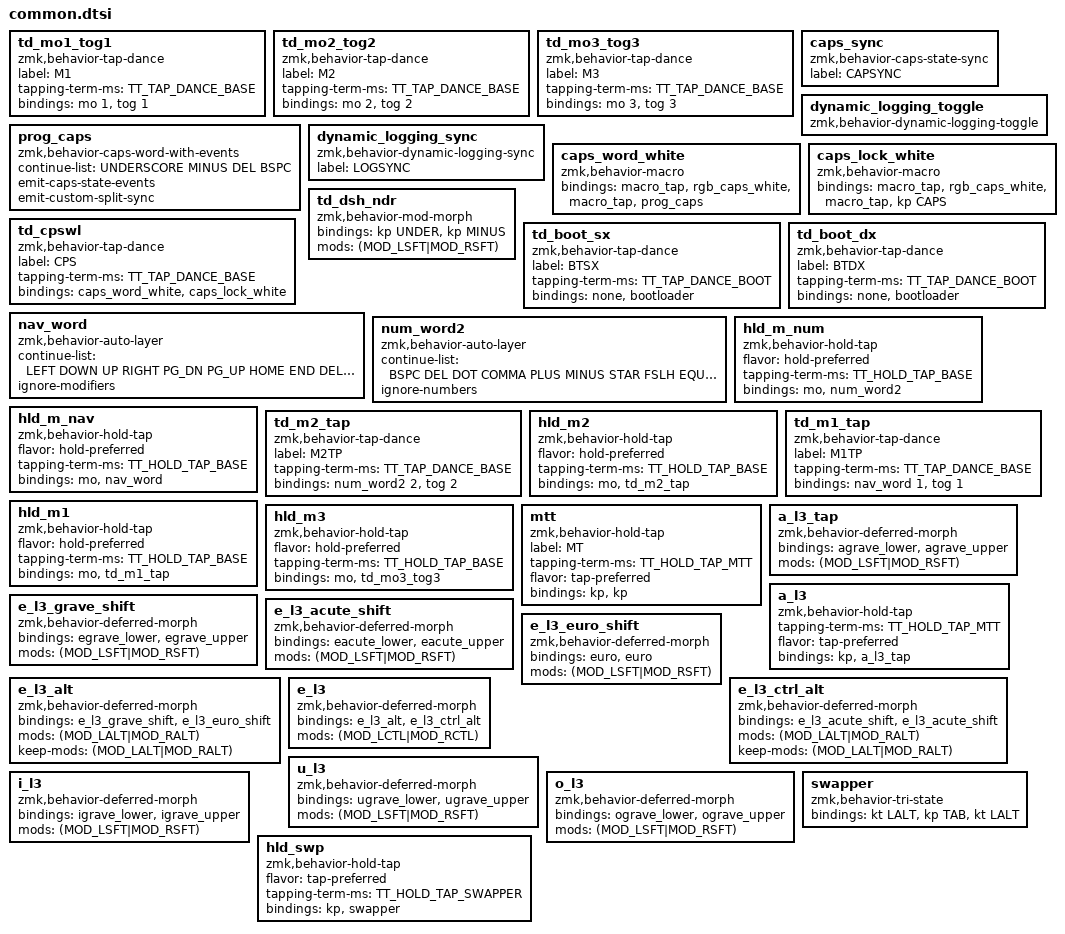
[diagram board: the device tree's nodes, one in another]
        /*
         * Mini-spec td_mo1_tog1
         * Input: tap dance su tasto M1.
         * Tap: layer momentaneo 1 (&mo 1).
         * Double tap: toggle persistente layer 1 (&tog 1).
         */
        td_mo1_tog1: td_mo1_tog1 {
            compatible = "zmk,behavior-tap-dance";
            label      = "M1";
            #binding-cells = <0>;
            tapping-term-ms = <TT_TAP_DANCE_BASE>;
            bindings = <&mo 1>, <&tog 1>;
        };

        /*
         * Mini-spec td_mo2_tog2
         * Input: tap dance su tasto M2.
         * Tap: layer momentaneo 2 (&mo 2).
         * Double tap: toggle persistente layer 2 (&tog 2).
         */
        td_mo2_tog2: td_mo2_tog2 {
            compatible = "zmk,behavior-tap-dance";
            label      = "M2";
            #binding-cells = <0>;
            tapping-term-ms = <TT_TAP_DANCE_BASE>;
            bindings = <&mo 2>, <&tog 2>;
        };

        /*
         * Mini-spec td_mo3_tog3
         * Input: tap dance su tasto M3.
         * Tap: layer momentaneo 3 (&mo 3).
         * Double tap: toggle persistente layer 3 (&tog 3).
         */
        td_mo3_tog3: td_mo3_tog3 {
            compatible = "zmk,behavior-tap-dance";
            label      = "M3";
            #binding-cells = <0>;
            tapping-term-ms = <TT_TAP_DANCE_BASE>;
            bindings = <&mo 3>, <&tog 3>;
        };

        prog_caps: prog_caps {
            compatible = "zmk,behavior-caps-word-with-events";
            #binding-cells = <0>;
            continue-list = <UNDERSCORE MINUS DEL BSPC>;
            emit-caps-state-events;
            emit-custom-split-sync;
        };

        caps_sync: caps_sync {
            compatible = "zmk,behavior-caps-state-sync";
            label = "CAPSYNC";
            #binding-cells = <2>;
        };

        dynamic_logging_toggle: dynamic_logging_toggle {
            compatible = "zmk,behavior-dynamic-logging-toggle";
            #binding-cells = <0>;
        };

        dynamic_logging_sync: dynamic_logging_sync {
            compatible = "zmk,behavior-dynamic-logging-sync";
            label = "LOGSYNC";
            #binding-cells = <2>;
        };

        caps_word_white: caps_word_white {
            compatible = "zmk,behavior-macro";
            #binding-cells = <0>;
            bindings = <&macro_tap &rgb_caps_white>, <&macro_tap &prog_caps>;
        };

        caps_lock_white: caps_lock_white {
            compatible = "zmk,behavior-macro";
            #binding-cells = <0>;
            bindings = <&macro_tap &rgb_caps_white>, <&macro_tap &kp CAPS>;
        };

        /*
         * Mini-spec td_cpswl
         * Input: tap dance su un tasto dedicato.
         * Tap: esegue caps_word_white (RGB bianco + Caps Word).
         * Double tap: esegue caps_lock_white (RGB bianco + Caps Lock).
         */
        td_cpswl: td_cpswl {
            compatible = "zmk,behavior-tap-dance";
            label      = "CPS";
            #binding-cells = <0>;
            tapping-term-ms = <TT_TAP_DANCE_BASE>;
            bindings = <&caps_word_white>, <&caps_lock_white>;
        };

        td_dsh_ndr: td_dsh_ndr {
            compatible = "zmk,behavior-mod-morph";
            #binding-cells = <0>;
            bindings = <&kp UNDER>, <&kp MINUS>;
            mods = <(MOD_LSFT|MOD_RSFT)>;
        };

        /*
         * Mini-spec td_boot_sx
         * Input: tap dance su tasto boot sinistro.
         * Tap: nessuna azione (&none).
         * Double tap: ingresso bootloader.
         */
        td_boot_sx: td_boot_sx {
            compatible = "zmk,behavior-tap-dance";
            label      = "BTSX";
            #binding-cells = <0>;
            tapping-term-ms = <TT_TAP_DANCE_BOOT>;
            bindings = <&none>, <&bootloader>;
        };

        /*
         * Mini-spec td_boot_dx
         * Input: tap dance su tasto boot destro.
         * Tap: nessuna azione (&none).
         * Double tap: ingresso bootloader.
         */
        td_boot_dx: td_boot_dx {
            compatible = "zmk,behavior-tap-dance";
            label      = "BTDX";
            #binding-cells = <0>;
            tapping-term-ms = <TT_TAP_DANCE_BOOT>;
            bindings = <&none>, <&bootloader>;
        };

        nav_word: nav_word {
            compatible = "zmk,behavior-auto-layer";
            #binding-cells = <1>;
            continue-list = <LEFT DOWN UP RIGHT PG_DN PG_UP HOME END DELETE BACKSPACE LC(X) LC(A) LC(C) LC(V) LG(V)>;
            ignore-modifiers;
        };

        num_word2: num_word2 {
            compatible = "zmk,behavior-auto-layer";
            #binding-cells = <1>;
            continue-list = <BSPC DEL DOT COMMA PLUS MINUS STAR FSLH EQUAL>;
            ignore-numbers;
        };

        /*
         * Mini-spec hld_m_num
         * Input: &hld_m_num <layer_hold> <layer_num_word>.
         * Tap: attiva num_word2 sul layer passato come secondo argomento.
         * Hold: attiva &mo sul layer passato come primo argomento.
         */
        hld_m_num: hld_m_num {
            compatible = "zmk,behavior-hold-tap";
            #binding-cells = <2>;
            flavor = "hold-preferred";
            tapping-term-ms = <TT_HOLD_TAP_BASE>;
            bindings = <&mo>, <&num_word2>;
        };

        /*
         * Mini-spec hld_m_nav
         * Input: &hld_m_nav <layer_hold> <layer_nav_word>.
         * Tap: attiva nav_word sul layer passato come secondo argomento.
         * Hold: attiva &mo sul layer passato come primo argomento.
         */
        hld_m_nav: hld_m_nav {
            compatible = "zmk,behavior-hold-tap";
            #binding-cells = <2>;
            flavor = "hold-preferred";
            tapping-term-ms = <TT_HOLD_TAP_BASE>;
            bindings = <&mo>, <&nav_word>;
        };

        /*
         * Mini-spec td_m2_tap
         * Input: tap path del tasto M2.
         * Tap: attiva num_word2 sul layer 2.
         * Double tap: toggle persistente del layer 2.
         */
        td_m2_tap: td_m2_tap {
            compatible = "zmk,behavior-tap-dance";
            label      = "M2TP";
            #binding-cells = <0>;
            tapping-term-ms = <TT_TAP_DANCE_BASE>;
            bindings = <&num_word2 2>, <&tog 2>;
        };

        /*
         * Mini-spec hld_m2
         * Input: &hld_m2 <layer_hold> <unused> su tasto M2.
         * Hold: attiva subito &mo sul layer passato come primo argomento.
         * Tap: esegue td_m2_tap (single=num_word2, double=tog 2).
         */
        hld_m2: hld_m2 {
            compatible = "zmk,behavior-hold-tap";
            #binding-cells = <2>;
            flavor = "hold-preferred";
            tapping-term-ms = <TT_HOLD_TAP_BASE>;
            bindings = <&mo>, <&td_m2_tap>;
        };

        /*
         * Mini-spec td_m1_tap
         * Input: tap path del tasto M1.
         * Tap: attiva nav_word sul layer 1.
         * Double tap: toggle persistente del layer 1.
         */
        td_m1_tap: td_m1_tap {
            compatible = "zmk,behavior-tap-dance";
            label      = "M1TP";
            #binding-cells = <0>;
            tapping-term-ms = <TT_TAP_DANCE_BASE>;
            bindings = <&nav_word 1>, <&tog 1>;
        };

        /*
         * Mini-spec hld_m1
         * Input: &hld_m1 <layer_hold> <unused> su tasto M1.
         * Hold: attiva subito &mo sul layer passato come primo argomento.
         * Tap: esegue td_m1_tap (single=nav_word, double=tog 1).
         */
        hld_m1: hld_m1 {
            compatible = "zmk,behavior-hold-tap";
            #binding-cells = <2>;
            flavor = "hold-preferred";
            tapping-term-ms = <TT_HOLD_TAP_BASE>;
            bindings = <&mo>, <&td_m1_tap>;
        };

        /*
         * Mini-spec hld_m3
         * Input: &hld_m3 <layer_hold> <unused> su tasto M3.
         * Hold: attiva subito &mo sul layer passato come primo argomento.
         * Tap: esegue td_mo3_tog3 (single=mo 3, double=tog 3).
         */
        hld_m3: hld_m3 {
            compatible = "zmk,behavior-hold-tap";
            #binding-cells = <2>;
            flavor = "hold-preferred";
            tapping-term-ms = <TT_HOLD_TAP_BASE>;
            bindings = <&mo>, <&td_mo3_tog3>;
        };

        /*
         * Mini-spec mtt
         * Input: &mtt <mod> <key>.
         * Tap: invia il keycode passato come secondo argomento.
         * Hold: mantiene il modificatore passato come primo argomento.
         */
        mtt: mtt {
            compatible       = "zmk,behavior-hold-tap";
            label            = "MT";
            #binding-cells = <2>;
            tapping-term-ms  = <TT_HOLD_TAP_MTT>;
            flavor           = "tap-preferred";
            bindings         = <&kp>, <&kp>;
        };

        a_l3_tap: a_l3_tap {
            compatible = "zmk,behavior-deferred-morph";
            #binding-cells = <0>;
            bindings = <&agrave_lower>, <&agrave_upper>;
            mods = <(MOD_LSFT|MOD_RSFT)>;
        };

        a_l3: a_l3 {
            compatible = "zmk,behavior-hold-tap";
            #binding-cells = <2>;
            tapping-term-ms = <TT_HOLD_TAP_MTT>;
            flavor = "tap-preferred";
            bindings = <&kp>, <&a_l3_tap>;
        };

        e_l3_grave_shift: e_l3_grave_shift {
            compatible = "zmk,behavior-deferred-morph";
            #binding-cells = <0>;
            bindings = <&egrave_lower>, <&egrave_upper>;
            mods = <(MOD_LSFT|MOD_RSFT)>;
        };

        e_l3_acute_shift: e_l3_acute_shift {
            compatible = "zmk,behavior-deferred-morph";
            #binding-cells = <0>;
            bindings = <&eacute_lower>, <&eacute_upper>;
            mods = <(MOD_LSFT|MOD_RSFT)>;
        };

        e_l3_euro_shift: e_l3_euro_shift {
            compatible = "zmk,behavior-deferred-morph";
            #binding-cells = <0>;
            bindings = <&euro>, <&euro>;
            mods = <(MOD_LSFT|MOD_RSFT)>;
        };

        e_l3_alt: e_l3_alt {
            compatible = "zmk,behavior-deferred-morph";
            #binding-cells = <0>;
            bindings = <&e_l3_grave_shift>, <&e_l3_euro_shift>;
            mods = <(MOD_LALT|MOD_RALT)>;
            /* Alt must stay unmasked: the euro macro itself needs Alt held for its numpad sequence. */
            keep-mods = <(MOD_LALT|MOD_RALT)>;
        };

        e_l3_ctrl_alt: e_l3_ctrl_alt {
            compatible = "zmk,behavior-deferred-morph";
            #binding-cells = <0>;
            bindings = <&e_l3_acute_shift>, <&e_l3_acute_shift>;
            mods = <(MOD_LALT|MOD_RALT)>;
            /* Both branches use Alt internally for their numpad sequence; never mask it. */
            keep-mods = <(MOD_LALT|MOD_RALT)>;
        };

        e_l3: e_l3 {
            compatible = "zmk,behavior-deferred-morph";
            #binding-cells = <0>;
            bindings = <&e_l3_alt>, <&e_l3_ctrl_alt>;
            mods = <(MOD_LCTL|MOD_RCTL)>;
        };

        u_l3: u_l3 {
            compatible = "zmk,behavior-deferred-morph";
            #binding-cells = <0>;
            bindings = <&ugrave_lower>, <&ugrave_upper>;
            mods = <(MOD_LSFT|MOD_RSFT)>;
        };

        i_l3: i_l3 {
            compatible = "zmk,behavior-deferred-morph";
            #binding-cells = <0>;
            bindings = <&igrave_lower>, <&igrave_upper>;
            mods = <(MOD_LSFT|MOD_RSFT)>;
        };

        o_l3: o_l3 {
            compatible = "zmk,behavior-deferred-morph";
            #binding-cells = <0>;
            bindings = <&ograve_lower>, <&ograve_upper>;
            mods = <(MOD_LSFT|MOD_RSFT)>;
        };

        swapper: swapper {
            compatible = "zmk,behavior-tri-state";
            #binding-cells = <0>;
            bindings = <&kt LALT>, <&kp TAB>, <&kt LALT>;
        };

        /*
         * Mini-spec hld_swp
         * Input: &hld_swp <tap_keycode> <unused>.
         * Tap: invia il keycode passato come primo argomento.
         * Hold: avvia il comportamento swapper (ciclo Alt-Tab).
         */
        hld_swp: hld_swp {
            compatible = "zmk,behavior-hold-tap";
            #binding-cells = <2>;
            flavor = "tap-preferred";
            tapping-term-ms = <TT_HOLD_TAP_SWAPPER>;
            bindings = <&kp>, <&swapper>;
        };
